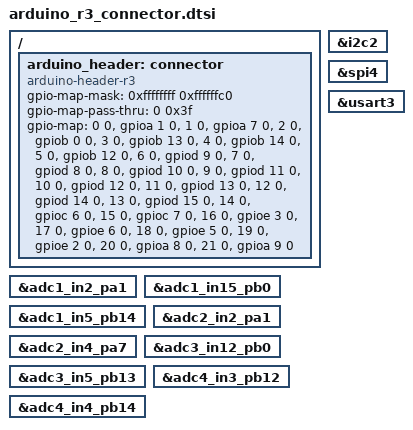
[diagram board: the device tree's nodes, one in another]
/*
 * Copyright (c) 2024 Frickly Systems GmbH
 *
 * SPDX-License-Identifier: Apache-2.0
*/

/ {
	arduino_header: connector {
		compatible = "arduino-header-r3";
		#gpio-cells = <2>;
		gpio-map-mask = <0xffffffff 0xffffffc0>;
		gpio-map-pass-thru = <0 0x3f>;
		gpio-map = <0 0 &gpioa 1 0>, /* A0 */
		           <1 0 &gpioa 7 0>, /* A1 */
		           <2 0 &gpiob 0 0>, /* A2 */
		           <3 0 &gpiob 13 0>, /* A3 */
		           <4 0 &gpiob 14 0>, /* A4 */
		           <5 0 &gpiob 12 0>, /* A5 */
		           <6 0 &gpiod 9 0>, /* D0 */
		           <7 0 &gpiod 8 0>, /* D1 */
		           <8 0 &gpiod 10 0>, /* D2 */
		           <9 0 &gpiod 11 0>, /* D3 */
		           <10 0 &gpiod 12 0>, /* D4 */
		           <11 0 &gpiod 13 0>, /* D5 */
		           <12 0 &gpiod 14 0>, /* D6 */
		           <13 0 &gpiod 15 0>, /* D7 */
		           <14 0 &gpioc 6 0>, /* D8 */
		           <15 0 &gpioc 7 0>, /* D9 */
		           <16 0 &gpioe 3 0>, /* D10 */
		           <17 0 &gpioe 6 0>, /* D11 */
		           <18 0 &gpioe 5 0>, /* D12 */
		           <19 0 &gpioe 2 0>, /* D13 */
		           <20 0 &gpioa 8 0>, /* D18 */
		           <21 0 &gpioa 9 0>;    /* D19 */
	};
};

arduino_i2c: &i2c2 {};
arduino_spi: &spi4 {};
arduino_serial: &usart3 {};


// adc pin labels for easier config
adc1_in2_A0: &adc1_in2_pa1 {};
adc1_in15_A2: &adc1_in15_pb0 {};
adc1_in5_A4: &adc1_in5_pb14 {};

adc2_in2_A0: &adc2_in2_pa1 {};
adc2_in4_A1: &adc2_in4_pa7 {};

adc3_in12_A2: &adc3_in12_pb0 {};
adc3_in5_A3: &adc3_in5_pb13 {};

adc4_in3_A5: &adc4_in3_pb12 {};
adc4_in4_A4: &adc4_in4_pb14 {};
